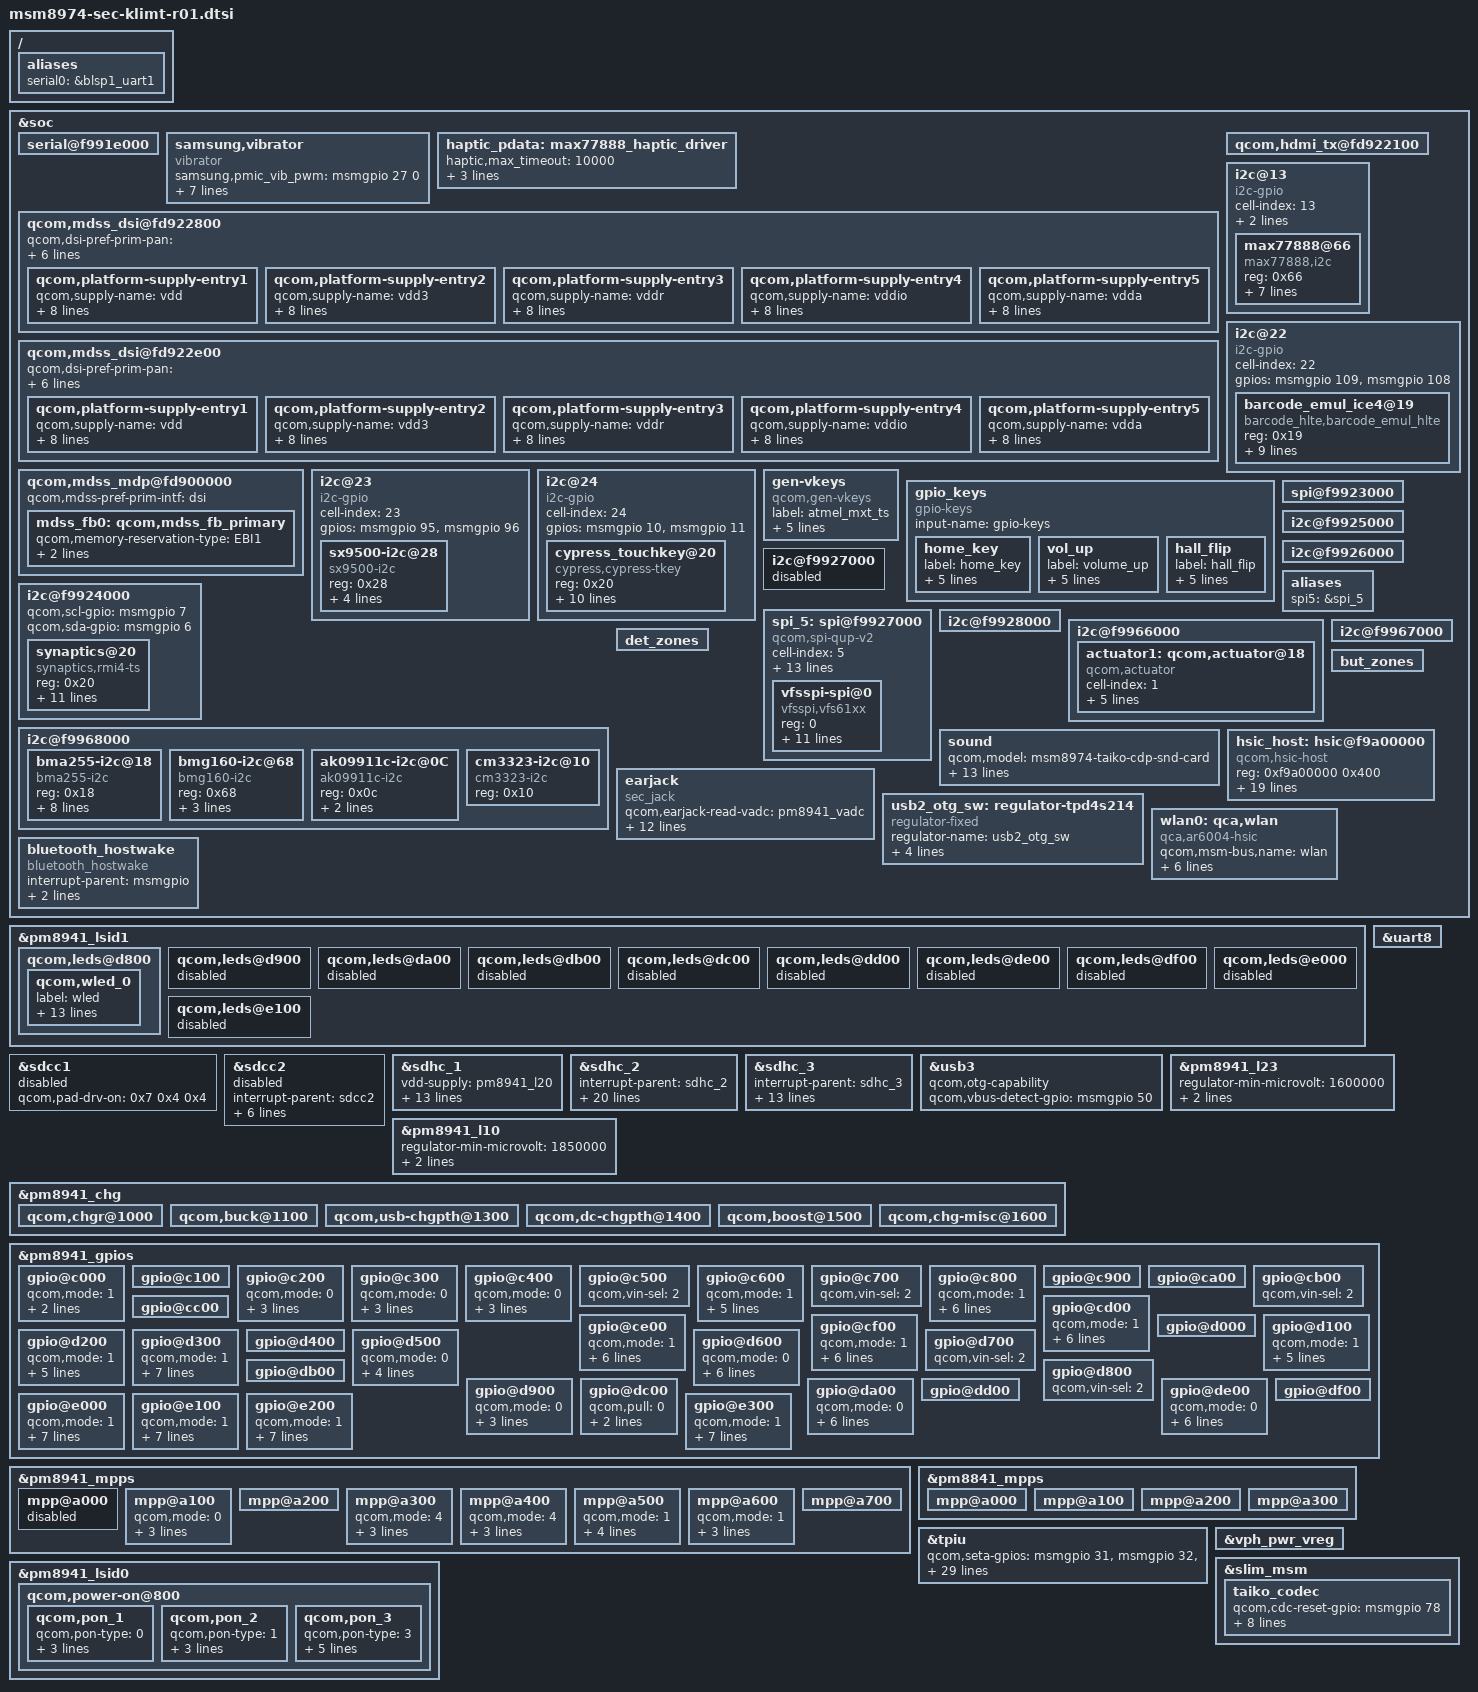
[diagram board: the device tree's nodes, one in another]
/* Copyright (c) 2012-2013, The Linux Foundation. All rights reserved.
 *
 * This program is free software; you can redistribute it and/or modify
 * it under the terms of the GNU General Public License version 2 and
 * only version 2 as published by the Free Software Foundation.
 *
 * This program is distributed in the hope that it will be useful,
 * but WITHOUT ANY WARRANTY; without even the implied warranty of
 * MERCHANTABILITY or FITNESS FOR A PARTICULAR PURPOSE.  See the
 * GNU General Public License for more details.
 */

/include/ "msm8974-leds.dtsi"
/include/ "msm8974-camera-sensor-klimt-r00.dtsi"
/include/ "msm8974-sii8240_mhl-mondrian-r00.dtsi"
/include/ "msm8974-sec-klimt-battery.dtsi"

/ {
	aliases {
		serial0 = &blsp1_uart1;
	};
};

&soc {
	serial@f991e000 {
		status = "ok";
	};

	samsung,vibrator {
		compatible = "vibrator";
		samsung,pmic_vib_pwm = <&msmgpio 27 0>;
		samsung,vib_power_en = <&msmgpio 91 0>;
		samsung,vib_model = <1>;
		samsung,pmic_vib_en = <0>;
		samsung,pmic_haptic_pwr_en = <0>;
		samsung,is_pmic_vib_pwm = <0>;
		samsung,pwm_period_us = <40>;
		samsung,duty_us = <36>;
		status = "ok";
	};
	haptic_pdata: max77888_haptic_driver{
		haptic,max_timeout = <10000>;
		haptic,duty = <44000>;
		haptic,period = <44642>;
		haptic,pwm_id = <1>;
	};
	qcom,mdss_dsi@fd922800 {
		qcom,dsi-pref-prim-pan = <&dsi_dual_2560p_cmd_s6e3ha1_right>;
		vdd-supply = <&pm8941_l22>;
		vdd3-supply = <&pm8941_lvs1>;
		vddr-supply = <&pm8941_l23>;
		vddio-supply = <&pm8941_l12>;
		vdda-supply = <&pm8941_l2>;
		qcom,platform-supply-entry1 {
				qcom,supply-name = "vdd";
				qcom,supply-min-voltage = <3000000>;
				qcom,supply-max-voltage = <3000000>;
				qcom,supply-enable-load = <100000>;
				qcom,supply-disable-load = <100>;
				qcom,supply-pre-on-sleep = <0>;
				qcom,supply-post-on-sleep = <5>;
				qcom,supply-pre-off-sleep = <0>;
				qcom,supply-post-off-sleep = <0>;
		};
		qcom,platform-supply-entry2 {
				qcom,supply-name = "vdd3";
				qcom,supply-min-voltage = <1800000>;
				qcom,supply-max-voltage = <1800000>;
				qcom,supply-enable-load = <100000>;
				qcom,supply-disable-load = <100>;
				qcom,supply-pre-on-sleep = <0>;
				qcom,supply-post-on-sleep = <5>;
				qcom,supply-pre-off-sleep = <0>;
				qcom,supply-post-off-sleep = <0>;
		};
		qcom,platform-supply-entry3 {
				qcom,supply-name = "vddr";
				qcom,supply-min-voltage = <1600000>;
				qcom,supply-max-voltage = <1600000>;
				qcom,supply-enable-load = <100000>;
				qcom,supply-disable-load = <100>;
				qcom,supply-pre-on-sleep = <0>;
				qcom,supply-post-on-sleep = <5>;
				qcom,supply-pre-off-sleep = <0>;
				qcom,supply-post-off-sleep = <0>;
		};

		qcom,platform-supply-entry4 {
				qcom,supply-name = "vddio";
				qcom,supply-min-voltage = <1800000>;
				qcom,supply-max-voltage = <1800000>;
				qcom,supply-enable-load = <100000>;
				qcom,supply-disable-load = <100>;
				qcom,supply-pre-on-sleep = <0>;
				qcom,supply-post-on-sleep = <5>;
				qcom,supply-pre-off-sleep = <0>;
				qcom,supply-post-off-sleep = <0>;
		};

		qcom,platform-supply-entry5 {
				qcom,supply-name = "vdda";
				qcom,supply-min-voltage = <1200000>;
				qcom,supply-max-voltage = <1200000>;
				qcom,supply-enable-load = <100000>;
				qcom,supply-disable-load = <100>;
				qcom,supply-pre-on-sleep = <0>;
				qcom,supply-post-on-sleep = <0>;
				qcom,supply-pre-off-sleep = <0>;
				qcom,supply-post-off-sleep = <0>;
		};
	};

	qcom,mdss_dsi@fd922e00 {
		qcom,dsi-pref-prim-pan = <&dsi_dual_2560p_cmd_s6e3ha1_left>;
		vdd-supply = <&pm8941_l22>;
		vdd3-supply = <&pm8941_lvs1>;
		vddr-supply = <&pm8941_l23>;
		vddio-supply = <&pm8941_l12>;
		vdda-supply = <&pm8941_l2>;
		qcom,platform-supply-entry1 {
				qcom,supply-name = "vdd";
				qcom,supply-min-voltage = <3000000>;
				qcom,supply-max-voltage = <3000000>;
				qcom,supply-enable-load = <100000>;
				qcom,supply-disable-load = <100>;
				qcom,supply-pre-on-sleep = <0>;
				qcom,supply-post-on-sleep = <5>;
				qcom,supply-pre-off-sleep = <0>;
				qcom,supply-post-off-sleep = <0>;
		};
		qcom,platform-supply-entry2 {
				qcom,supply-name = "vdd3";
				qcom,supply-min-voltage = <1800000>;
				qcom,supply-max-voltage = <1800000>;
				qcom,supply-enable-load = <100000>;
				qcom,supply-disable-load = <100>;
				qcom,supply-pre-on-sleep = <0>;
				qcom,supply-post-on-sleep = <5>;
				qcom,supply-pre-off-sleep = <0>;
				qcom,supply-post-off-sleep = <0>;
		};
		qcom,platform-supply-entry3 {
				qcom,supply-name = "vddr";
				qcom,supply-min-voltage = <1600000>;
				qcom,supply-max-voltage = <1600000>;
				qcom,supply-enable-load = <100000>;
				qcom,supply-disable-load = <100>;
				qcom,supply-pre-on-sleep = <0>;
				qcom,supply-post-on-sleep = <5>;
				qcom,supply-pre-off-sleep = <0>;
				qcom,supply-post-off-sleep = <0>;
		};

		qcom,platform-supply-entry4 {
				qcom,supply-name = "vddio";
				qcom,supply-min-voltage = <1800000>;
				qcom,supply-max-voltage = <1800000>;
				qcom,supply-enable-load = <100000>;
				qcom,supply-disable-load = <100>;
				qcom,supply-pre-on-sleep = <0>;
				qcom,supply-post-on-sleep = <5>;
				qcom,supply-pre-off-sleep = <0>;
				qcom,supply-post-off-sleep = <0>;
		};

		qcom,platform-supply-entry5 {
				qcom,supply-name = "vdda";
				qcom,supply-min-voltage = <1200000>;
				qcom,supply-max-voltage = <1200000>;
				qcom,supply-enable-load = <100000>;
				qcom,supply-disable-load = <100>;
				qcom,supply-pre-on-sleep = <0>;
				qcom,supply-post-on-sleep = <0>;
				qcom,supply-pre-off-sleep = <0>;
				qcom,supply-post-off-sleep = <0>;
		};
	};

	qcom,mdss_mdp@fd900000 {
		qcom,mdss-pref-prim-intf = "dsi";
		mdss_fb0: qcom,mdss_fb_primary {
			qcom,memory-reservation-type = "EBI1";
			qcom,memblock-reserve = <0x03200000 0x01F00000>;
			qcom,mdss-fb-split = <800 800>;
		};
	};

	qcom,hdmi_tx@fd922100 {
		status = "ok";
	};

    i2c@13 {
        cell-index = <13>;
        compatible = "i2c-gpio";
        gpios = <&msmgpio 83 0 /* sda */
                 &msmgpio 84 0 /* scl */
                >;
		i2c-gpio,delay-us = <2>;
		#address-cells = <1>;
		#size-cells = <0>;
		max77888@66 {
		    compatible = "max77888,i2c";
		    reg = <0x66>;
		    interrupt-parent = <&pm8941_gpios>;
		    interrupts = <23 0>,
		    		 <27 0>;
		    max77888,irq-gpio = <&pm8941_gpios 23 0x00>;
		    max77888,irq-reset-gpio = <&pm8941_gpios 27 0x00>;
		    max77888,irq-base = <357>;
		    max77888,wakeup = <1>;
		    max77888,haptic = <&haptic_pdata>;
		};
    };

	i2c@22 {
		cell-index = <22>;
		compatible = "i2c-gpio";
		gpios = <&msmgpio 109 0 /* sda */
		&msmgpio 108 0 /* scl */
		>;

		barcode_emul_ice4@19 {
			compatible = "barcode_hlte,barcode_emul_hlte";
			reg = <0x19>;
			interrupt-parent = <&msmgpio>;
			interrupts = <64 0>;
			vdd-supply = <&pm8941_l19>;
			barcode,cresetb = <&msmgpio 57 0x01>;
			barcode,reset_n = <&msmgpio 132 0x00>;
			barcode,scl-gpio = <&msmgpio 108 0x00>;
			barcode,sda-gpio = <&msmgpio 109 0x00>;
			barcode,irq-gpio = <&msmgpio 64 0x00>;
			barcode,i2c-pull-up = <1>;
		};
	};

	i2c@23 {
		cell-index = <23>;
		compatible = "i2c-gpio";
		gpios = <&msmgpio 95 0 /* sda */
		&msmgpio 96 0 /* scl */
		>;
		sx9500-i2c@28 {
			compatible = "sx9500-i2c";
			reg = <0x28>;
			sx9500-i2c,nirq-gpio = <&pm8941_mpps 2 0x00>;
			sx9500-i2c,scl-gpio = <&msmgpio 96 0x00>;
			sx9500-i2c,sda-gpio = <&msmgpio 95 0x00>;
			sx9500-i2c,i2c-pull-up = <1>;
		};
	};

	i2c@24 {
		cell-index = <24>;
		compatible = "i2c-gpio";
		gpios = <&msmgpio 10 0 /* sda */
				&msmgpio 11 0 /* scl */
		>;


		cypress_touchkey@20 {
			compatible = "cypress,cypress-tkey";
			reg = <0x20>;
			interrupt-parent = <&msmgpio>;
			interrupts = <144 0>;
			vdd_led-supply = <&pm8941_l19>;
			vcc_en-supply = <&pm8941_l10>;
			vdd_led-gpio = <&pm8941_gpios 12 0x00>; /* TCON_EN */
			cypress,scl-gpio = <&msmgpio 11 0x00>;
			cypress,sda-gpio = <&msmgpio 10 0x00>;
			cypress,irq-gpio = <&msmgpio 144 0x1>;
			cypress,tkey-keycodes = <254 158>;
			cypress,i2c-pull-up = <1>;
		};

/*
		i2c-gpio,delay-us = <4>;

		lp8556_backlight@2C {
				compatible = "lp8556,backlight-control";
				reg = <0x2C>;
				lp8556,en-gpio = <&pm8941_gpios 19 0x00>;
				lp8556,scl-gpio = <&msmgpio 11 0x00>;
				lp8556,sda-gpio = <&msmgpio 10 0x00>;
		};
*/
	};

	qcom,hdmi_tx@fd922100 {
		status = "ok";
	};



	gen-vkeys {
		compatible = "qcom,gen-vkeys";
		label = "atmel_mxt_ts";
		qcom,disp-maxx = <720>;
		qcom,disp-maxy = <1280>;
		qcom,panel-maxx = <760>;
		qcom,panel-maxy = <1424>;
		qcom,key-codes = <158 139 102 217>;
	};

	gpio_keys {
		compatible = "gpio-keys";
		input-name = "gpio-keys";

		home_key {
			label = "home_key";
			gpios = <&pm8941_gpios 3 0x1>;
			linux,input-type = <1>;
			linux,code = <172>;
			gpio-key,wakeup;
			debounce-interval = <15>;
		};
/*
		vol_down {
			label = "volume_down";
			gpios = <&pm8941_gpios 2 0x1>;
			linux,input-type = <1>;
			linux,code = <114>;
			gpio-key,wakeup;
			debounce-interval = <15>;
		};
*/
		vol_up {
			label = "volume_up";
			gpios = <&pm8941_gpios 5 0x1>;
			linux,input-type = <1>;
			linux,code = <115>;
			gpio-key,wakeup;
			debounce-interval = <15>;
		};

		hall_flip {
			label = "hall_flip";
			gpios = <&pm8941_gpios 31 0>;
			linux,input-type = <1>;
			linux,code = <0x15>;
			gpio-key,wakeup;
			debounce-interval = <15>;
		};
	};

	/* BLSP#1 */
	spi@f9923000 {
		status = "okay";
	};

	/* BLSP#2 */
	i2c@f9924000 {
		status = "okay";
		qcom,scl-gpio = <&msmgpio 7 0>;
		qcom,sda-gpio = <&msmgpio 6 0>;
		synaptics@20 {
			compatible = "synaptics,rmi4-ts";
			reg = <0x20>;
			interrupt-parent = <&pm8941_gpios>;
			interrupts = <30 0>;
			synaptics,supply-num = <1>;			/* the number of regulators */
			synaptics,supply-name = "8941_l10";	/* the name of regulators, in power-on order */
			synaptics,external_ldo = <&pm8941_gpios 10 0x1>;
			synaptics,irq-gpio = <&pm8941_gpios 30 0x1>;
			synaptics,reset-gpio = <&pm8941_gpios 20 0x1>;
			synaptics,i2c-pull-up = <1>;
			synaptics,tsp-project = "Klimt";
			synaptics,tsp-coords = <1599 2559>;
			synaptics,tsp-extra_config = <0 0 0 0>; /* <"pwrctrl", "N", "N", "N"> */
			/* Set regulators' voltage below. Search with "8941_l22", "8941_l10" */
		};
	};

	/* BLSP#3 */
	i2c@f9925000 {
	};

	/* BLSP#4 */
	i2c@f9926000 {
	};

	/* BLSP#5 */
	i2c@f9927000 {
		status = "disabled";
	};
	aliases {
		spi5 = &spi_5;
	};
	spi_5: spi@f9927000 {
		status = "okay";
		compatible = "qcom,spi-qup-v2";
		cell-index = <5>;
		#address-cells = <1>;
		#size-cells = <0>;
		reg = <0xf9927000 0x1000>,
			<0xf9904000 0x19000>;
		reg-names = "spi_physical", "spi_bam_physical";
		interrupt-names = "spi_irq", "spi_bam_irq";
		interrupts = <0 99 0>, <0 238 0>;
		spi-max-frequency = <19200000>;

		qcom,gpio-mosi = <&msmgpio 23 0>;
		qcom,gpio-miso = <&msmgpio 24 0>;
		qcom,gpio-clk  = <&msmgpio 26 0>;
		qcom,gpio-cs0  = <&msmgpio 25 0>;

		qcom,infinite-mode = <0>;
		qcom,use-bam;
		qcom,ver-reg-exists;
		qcom,bam-consumer-pipe-index = <20>;
		qcom,bam-producer-pipe-index = <21>;
		qcom,master-id = <86>;

		vfsspi-spi@0 {
			compatible = "vfsspi,vfs61xx";
			reg = <0>;
			spi-max-frequency = <19200000>;
			vfsspi-sleepPin = <&msmgpio 73 0x00>;
			vfsspi-drdyPin = <&msmgpio 94 0x01>;
			vfsspi-ldoPin = <&pm8941_gpios 18 0x00>; /* LDO_EN_1.8V */
			vfsspi-ldoPin2 = <&pm8941_gpios 19 0x00>; /* LDO_EN_3.3V */
			/* vfsspi-ocpflag = <&pm8941_gpios 7 0x00>; */
			/* vfsspi-ocpen = <&msmgpio 63 0x00>; */
			vfsspi-mosipin = <23>;
			vfsspi-misopin = <24>;
			vfsspi-cspin = <25>;
			vfsspi-clkpin = <26>;
			vfsspi-orient = <0>;
			vfsspi-ldocontrol= <1>;
			};
	};

	/* BLSP#6 */
	i2c@f9928000 {
		status = "okay";
	};

	/* BLSP#7 */
	/* i2c@f9963000 {
	}; */

	/* BLSP#8 */
	/* i2c@f9964000 {
	}; */

	/* BLSP#10 */
	i2c@f9966000 {
		actuator1: qcom,actuator@18 {
			compatible = "qcom,actuator";
			cell-index = <1>;
			reg = <0x18>;
			gpios = <&msmgpio 55 0>,
					<&msmgpio 56 0>;
			qcom,gpio-req-tbl-num = <0 1>;
			qcom,gpio-req-tbl-flags = <1 1>;
			qcom,gpio-req-tbl-label = "I2C_DATA0",
							  		"I2C_CLK0";
		};
	};

	/* BLSP#11 */
	i2c@f9967000 {
	};

	/* BLSP#12 */
	i2c@f9968000 {
		status = "okay";
		bma255-i2c@18 {
			compatible = "bma255-i2c";
			reg = <0x18>;
			interrupt-parent = <&msmgpio>;
			interrupts = <86 0>;
			bma255-i2c,scl = <&msmgpio 88 0>;
			bma255-i2c,sda = <&msmgpio 87 0>;
			bma255-i2c,acc_int1-gpio = <&msmgpio 86 0x00>;
			bma255-i2c,chip_pos = <4>;
			bma255-i2c,vdd-supply = <&pm8941_l18>;
			bma255-i2c,vdd-io-supply = <&pm8941_lvs1>;
		};
		bmg160-i2c@68 {
			compatible = "bmg160-i2c";
			reg = <0x68>;
			interrupt-parent = <&msmgpio>;
			interrupts = <74 0>;
			bmg160-i2c,chip_pos = <4>;
		};
		ak09911c-i2c@0C {
			compatible = "ak09911c-i2c";
			reg = <0x0c>;
			ak09911c-i2c,m_rst_n-gpio = <&msmgpio 80 0x01>;
			ak09911c-i2c,chip_pos = <5>;
		};
		cm3323-i2c@10 {
			compatible = "cm3323-i2c";
			reg = <0x10>;
		};
	};

	sound {
		qcom,model = "msm8974-taiko-cdp-snd-card";
		qcom,hdmi-audio-rx;
		qcom,mainmic-bias-gpio = <&pm8941_gpios 33 0>;
		qcom,submic-bias-gpio = <&pm8941_gpios 35 0>;
		qcom,spkamp-en-gpio = <&msmgpio 82 0>;

		qcom,audio-routing =
			"RX_BIAS", "MCLK",
			"LDO_H", "MCLK",
			"AIF4 MAD", "MCLK",
			"Lineout_1 amp", "LINEOUT1",
			"Lineout_2 amp", "LINEOUT2",
			"Lineout_3 amp", "LINEOUT3",
			"Lineout_4 amp", "LINEOUT4",
			"AMIC4", "Main Mic Bias",
			"Main Mic Bias", "Main Mic",
			"AMIC2", "MIC BIAS2 External",
			"MIC BIAS2 External", "Headset Mic",
			"AMIC3", "Sub Mic Bias",
			"Sub Mic Bias", "Sub Mic";
	};

	det_zones: det_zones {
		#list-det-cells = <4>;
	};

	but_zones: but_zones {
		#list-but-cells = <3>;
	};

	earjack {
		compatible = "sec_jack";
		qcom,earjack-read-vadc = <&pm8941_vadc>;
		qcom,earjack-detect-gpio = <&pm8941_gpios 22 0>;
		qcom,earjack-micbias-gpio = <&pm8941_gpios 34 0>;
		qcom,earjack-sendend-gpio = <&msmgpio 77 0>;
		qcom,earjack-fsa_en-gpio = <&msmgpio 8 1>;
		qcom,send-end-active-high;

		det-zones-list = <&det_zones 0 10000 10 0>,
						 <&det_zones 900 10000 10 0>,
						 <&det_zones 2400 10000 10 1>,
						 <&det_zones 9999 10000 10 1>;
		but-zones-list = <&but_zones 0 0 155>,
						 <&but_zones 1 156 310>,
						 <&but_zones 2 311 800>;
		mpp-channel-scaling = <4 1 3>;
	};

	usb2_otg_sw: regulator-tpd4s214 {
		compatible = "regulator-fixed";
		regulator-name = "usb2_otg_sw";
		gpio = <&pm8941_gpios 18 0>;
		parent-supply = <&pm8941_boost>;
		startup-delay-us = <17000>;
		enable-active-high;
	};

	hsic_host: hsic@f9a00000 {
		compatible = "qcom,hsic-host";
		reg = <0xf9a00000 0x400>;
		#address-cells = <0>;
		interrupt-parent = <&hsic_host>;
		interrupts = <0 1 2>;
		#interrupt-cells = <1>;
		interrupt-map-mask = <0xffffffff>;
		interrupt-map = <0 &intc 0 136 0
			1 &intc 0 148 0
			2 &msmgpio 144 0x8>;
		interrupt-names = "core_irq", "async_irq", "wakeup";
		HSIC_VDDCX-supply = <&pm8841_s2>;
		HSIC_GDSC-supply = <&gdsc_usb_hsic>;
		hsic,strobe-gpio = <&msmgpio 144 0x00>;
		hsic,data-gpio = <&msmgpio 145 0x00>;
		hsic,resume-gpio = <&msmgpio 80 0x00>;
		hsic,ignore-cal-pad-config;
		hsic,strobe-pad-offset = <0x2050>;
		hsic,data-pad-offset = <0x2054>;
		qcom,phy-susp-sof-workaround;

		qcom,msm-bus,name = "hsic";
		qcom,msm-bus,num-cases = <2>;
		qcom,msm-bus,num-paths = <1>;
		qcom,msm-bus,vectors-KBps =
				<85 512 0 0>,
				<85 512 40000 160000>;
        };

	wlan0: qca,wlan {
		compatible = "qca,ar6004-hsic";
		qcom,msm-bus,name = "wlan";
		qcom,msm-bus,num-cases = <5>;
		qcom,msm-bus,active-only = <0>;
		qcom,msm-bus,num-paths = <1>;
		qcom,msm-bus,vectors-KBps =
				<85 512 0 0>,
				<85 512 40000 160000>,
				<85 512 40000 320000>,
				<85 512 40000 480000>,
				<85 512 40000 800000>;
	};
	bluetooth_hostwake{
		compatible = "bluetooth_hostwake";
		interrupt-parent = <&msmgpio>;
		interrupts = <75 0>;
		bluetooth_hostwake,irq-gpio = <&msmgpio 75 0x00>;
	};
};

&pm8941_lsid1 {
	qcom,leds@d800 {
		status = "okay";
		qcom,wled_0 {
			label = "wled";
			linux,name = "wled:backlight";
			linux,default-trigger = "bkl-trigger";
			qcom,cs-out-en;
			qcom,op-fdbck = <1>;
			qcom,default-state = "off";
			qcom,max-current = <25>;
			qcom,ctrl-delay-us = <0>;
			qcom,boost-curr-lim = <5>;
			qcom,cp-sel = <0>;
			qcom,switch-freq = <11>;
			qcom,ovp-val = <2>;
			qcom,num-strings = <3>;
			qcom,id = <0>;
		};
	};

	qcom,leds@d900 {
		status = "disabled";
	};

	qcom,leds@da00 {
		status = "disabled";
	};

	qcom,leds@db00 {
		status = "disabled";
	};

	qcom,leds@dc00 {
		status = "disabled";
	};

	qcom,leds@dd00 {
		status = "disabled";
	};

	qcom,leds@de00 {
		status = "disabled";
	};

	qcom,leds@df00 {
		status = "disabled";
	};

	qcom,leds@e000 {
		status = "disabled";
	};

	qcom,leds@e100 {
		status = "disabled";
	};
};

&sdcc1 {
       status = "disabled";
};

&sdcc2 {
	#address-cells = <0>;
	interrupt-parent = <&sdcc2>;
	interrupts = <0 1 2>;
	#interrupt-cells = <1>;
	interrupt-map-mask = <0xffffffff>;
	interrupt-map = <0 &intc 0 125 0
			1 &intc 0 220 0
			2 &msmgpio 62 0x3>;
	interrupt-names = "core_irq", "bam_irq", "status_irq";
	cd-gpios = <&msmgpio 62 0x1>;
	status = "disabled";
};

&sdhc_1 {
	vdd-supply = <&pm8941_l20>;
	vdd-io-supply = <&pm8941_s3>;

	qcom,vdd-always-on;
	qcom,vdd-lpm-sup;
	qcom,vdd-voltage-level = <2950000 2950000>;
	qcom,vdd-current-level = <800 500000>;

	qcom,vdd-io-always-on;
	qcom,vdd-io-voltage-level = <1800000 1800000>;
	qcom,vdd-io-current-level = <250 154000>;

	qcom,pad-pull-on = <0x0 0x3 0x3>; /* no-pull, pull-up, pull-up */
	qcom,pad-pull-off = <0x0 0x3 0x3>; /* no-pull, pull-up, pull-up */
	qcom,pad-drv-on = <0x4 0x4 0x4>; /* 10mA, 10mA, 10mA */
	qcom,pad-drv-off = <0x0 0x0 0x0>; /* 2mA, 2mA, 2mA */

	qcom,nonremovable;
	status = "ok";
};

&sdhc_2 {
	#address-cells = <0>;
	interrupt-parent = <&sdhc_2>;
	interrupts = <0 1>;
	#interrupt-cells = <1>;
	interrupt-map-mask = <0xffffffff>;
	interrupt-map = <0 &intc 0 125 0
			1 &intc 0 221 0>;
	interrupt-names = "hc_irq", "pwr_irq";
	//cd-gpios = <&msmgpio 62 0x1>;

	vdd-supply = <&pm8941_s3>;
	vdd-io-supply = <&pm8941_s3>;

	qcom,vdd-always-on;
	qcom,vdd-voltage-level = <1800000 1800000>;
	qcom,vdd-current-level = <2000 32000>;

	qcom,vdd-io-always-on;
	qcom,vdd-io-voltage-level = <1800000 1800000>;
	qcom,vdd-io-current-level = <2000 32000>;

	qcom,pad-pull-on = <0x0 0x3 0x3>; /* no-pull, pull-up, pull-up */
	qcom,pad-pull-off = <0x0 0x3 0x3>; /* no-pull, pull-up, pull-up */
	qcom,pad-drv-on = <0x7 0x4 0x3>; /* 16mA, 10mA, 8mA */
	qcom,pad-drv-off = <0x0 0x0 0x0>; /* 2mA, 2mA, 2mA */

	qcom,current-limit = <32000>;

	qcom,clk-rates = <400000 20000000 25000000 50000000 100000000 200000000>;

	qcom,sup-voltages = <2950 2950>;

	status-cb = <2>;
	status = "ok";
};

&sdhc_3 {
	#address-cells = <0>;
	interrupt-parent = <&sdhc_3>;
	interrupts = <0 1 2>;
	#interrupt-cells = <1>;
	interrupt-map-mask = <0xffffffff>;
	interrupt-map = <0 &intc 0 127 0
			1 &intc 0 224 0
			2 &msmgpio 62 0x3>;
	interrupt-names = "hc_irq", "pwr_irq", "status_irq";

	vdd-supply = <&pm8941_l21>;
	vdd-io-supply = <&pm8941_l21>;

	qcom,vdd-voltage-level = <2950000 2950000>;
	qcom,vdd-current-level = <9000 800000>;
	qcom,vdd-io-voltage-level = <2950000 2950000>;
	qcom,vdd-io-current-level = <6 22000>;
	qcom,sup-voltages = <2950 2950>;

	cd-gpios = <&msmgpio 62 0x1>;
	wp-gpios = <&pm8941_gpios 29 0x1>;

	status = "ok";
};

/* Drive strength recommendations for clock line from hardware team is 10 mA.
 * But since the driver has been been using the below values from the start
 * without any problems, continue to use those.
 */
&sdcc1 {
	qcom,pad-drv-on = <0x7 0x4 0x4>; /* 16mA, 10mA, 10mA */
};

&sdcc2 {
	qcom,pad-drv-on = <0x7 0x4 0x4>; /* 16mA, 10mA, 10mA */
};

&sdhc_1 {
	qcom,pad-drv-on = <0x7 0x4 0x4>; /* 16mA, 10mA, 10mA */
};

&sdhc_2 {
	qcom,pad-drv-on = <0x7 0x4 0x3>; /* 16mA, 10mA, 8mA */
};

&uart8 {
	status = "ok";
};

&usb3 {
	qcom,otg-capability;
	qcom,vbus-detect-gpio = <&msmgpio 50 0>;
};

&pm8941_l23 {
/* OCTA 1.6V VDDR regulator */
	regulator-min-microvolt = <1600000>;
	regulator-max-microvolt = <1600000>;
	qcom,init-voltage = <1600000>;
};

&pm8941_l10 {
/* TSP 1.8V IO regulator */
	regulator-min-microvolt = <1850000>;
	regulator-max-microvolt = <1850000>;
	qcom,init-voltage = <1850000>;
};

&pm8941_chg {
	status = "ok";

	qcom,chgr@1000 {
		status = "ok";
	};

	qcom,buck@1100 {
		status = "ok";
	};

	qcom,usb-chgpth@1300 {
		status = "ok";
	};

	qcom,dc-chgpth@1400 {
		status = "ok";
	};

	qcom,boost@1500 {
		status = "ok";
	};

	qcom,chg-misc@1600 {
		status = "ok";
	};
};

&pm8941_gpios {
	gpio@c000 { /* GPIO 1 */
		/* CAM_MOVIE_EN pin */
		qcom,mode = <1>;	/* DIG_OUT */
		qcom,pull = <4>;	/* QPNP_PIN_PULL_DOWN */
		qcom,vin-sel = <2>;		/* PM8941 S3 = 1.8 V */
	};

	gpio@c100 { /* GPIO 2 */
	};

	gpio@c200 { /* GPIO 3 */
		qcom,mode = <0>;
		qcom,pull = <0>;
		qcom,vin-sel = <2>;
		qcom,src-sel = <0>;
	};

	gpio@c300 { /* GPIO 4 */
		qcom,mode = <0>;
		qcom,pull = <0>;
		qcom,vin-sel = <2>;
		qcom,src-sel = <0>;
	};

	gpio@c400 { /* GPIO 5 */
		qcom,mode = <0>;
		qcom,pull = <0>;
		qcom,vin-sel = <2>;
		qcom,src-sel = <0>;
	};

	gpio@c500 { /* GPIO 6 */
		/* VT_CAM_STBY */
		qcom,vin-sel = <2>;		/* QPNP_PIN_VIN2 */
	};

	gpio@c600 { /* GPIO 7 */
		/* fingerprint sensor OCP_FLAG */
		qcom,mode = <1>;			/* Digital output */
		qcom,output-type = <0>;
		qcom,vin-sel = <2>;
		qcom,out-strength = <1>;	/* Low drive strength */
		qcom,src-sel = <0>;
		qcom,master-en = <1>;		/* Enable GPIO */
	};

	gpio@c700 { /* GPIO 8 */
		/* 2M_A2.8V_EN */
		qcom,vin-sel = <2>;		/* PM8941 S3 = 1.8 V */
	};

	gpio@c800 { /* GPIO 9 */
		qcom,mode = <1>;  /* QPNP_PIN_MODE_DIG_OUT */
		qcom,output-type = <0>; /* QPNP_PIN_OUT_BUF_CMOS */
		qcom,pull = <5>; /* QPNP_PIN_PULL_NO */
		qcom,vin-sel = <2>; /* QPNP_PIN_VIN2 */
		qcom,out-strength = <3>; /* QPNP_PIN_OUT_STRENGTH_HIGH */
		qcom,src-sel = <0>; /* QPNP_PIN_SEL_FUNC_CONSTANT */
		qcom,master-en = <1>;
	};

	gpio@c900 { /* GPIO 10 */
	};

	gpio@ca00 { /* GPIO 11 */
	};

	gpio@cb00 { /* GPIO 12 */
		/* 8M_AVDD_LDO_EN */
		qcom,vin-sel = <2>;		/* PM8941 S3 = 1.8 V */
	};

	gpio@cc00 { /* GPIO 13 */
	};

	gpio@cd00 { /* GPIO 14 */
		qcom,mode = <1>;  /* QPNP_PIN_MODE_DIG_OUT */
		qcom,output-type = <0>; /* QPNP_PIN_OUT_BUF_CMOS */
		qcom,pull = <5>; /* QPNP_PIN_PULL_NO */
		qcom,vin-sel = <2>; /* QPNP_PIN_VIN2 */
		qcom,out-strength = <3>; /* QPNP_PIN_OUT_STRENGTH_HIGH */
		qcom,src-sel = <0>; /* QPNP_PIN_SEL_FUNC_CONSTANT */
		qcom,master-en = <1>;
	};

	gpio@ce00 { /* GPIO 15 */
		qcom,mode = <1>;
		qcom,output-type = <0>;
		qcom,pull = <5>;
		qcom,vin-sel = <2>;
		qcom,out-strength = <1>;
		qcom,src-sel = <2>;
		qcom,master-en = <1>;
	};

	gpio@cf00 { /* GPIO 16 used for BT sleep_clk*/
		qcom,mode = <1>;
		qcom,output-type = <0>;
		qcom,pull = <5>;
		qcom,out-strength = <3>;
		qcom,vin-sel = <2>;
		qcom,src-sel = <3>;
		qcom,master_en = <1>;
	};

	gpio@d000 { /* GPIO 17 */
	};

	gpio@d100 { /* GPIO 18 */
		/* fingerprint sensor BTP_LDO_EN */
		qcom,mode = <1>;			/* Digital output */
		qcom,output-type = <0>;
		qcom,vin-sel = <2>;
		qcom,out-strength = <1>;	/* Low drive strength */
		qcom,src-sel = <0>;
		qcom,master-en = <1>;		/* Enable GPIO */
	};

	gpio@d200 { /* GPIO 19 */
		/* fingerprint sensor BTP_LDO_EN2 */
		qcom,mode = <1>;			/* Digital output */
		qcom,output-type = <0>;
		qcom,vin-sel = <2>;
		qcom,out-strength = <1>;	/* Low drive strength */
		qcom,src-sel = <0>;
		qcom,master-en = <1>;		/* Enable GPIO */
	};

	gpio@d300 { /* GPIO 20 */
		qcom,mode = <1>;		/* QPNP_PIN_MODE_DIG_OUT */
		qcom,output-type = <0>;		/* QPNP_PIN_OUT_BUF_CMOS */
		qcom,invert = <0>;		/* Output low initially */
		qcom,pull = <5>;		/* QPNP_PIN_PULL_NO */
		qcom,vin-sel = <2>;		/* QPNP_PIN_VIN2 */
		qcom,out-strength = <3>;	/* QPNP_PIN_OUT_STRENGTH_HIGH */
		qcom,src-sel = <0>;		/* QPNP_PIN_SEL_FUNC_CONSTANT */
		qcom,master-en = <1>;		/* Enable GPIO */
	};

	gpio@d400 { /* GPIO 21 */
	};

	gpio@d500 { /* GPIO 22 */
		qcom,mode = <0>;	/* input */
		qcom,pull = <5>;		/* pull-up with 30uA current strength */
		qcom,vin-sel = <2>;	/* VIN=S3 */
		qcom,src-sel = <0>;	/* constant */
		qcom,master_en = <1>;
	};

	gpio@d600 { /* GPIO 23 */
		qcom,mode = <0>;		/* QPNP_PIN_MODE_DIG_IN */
		qcom,output-type = <0>;		/* QPNP_PIN_OUT_BUF_CMOS */
		qcom,pull = <5>;		/* QPNP_PIN_PULL_NO */
		qcom,vin-sel = <2>; 		/* QPNP_PIN_VIN2 */
		qcom,out-strength = <3>;	/* QPNP_PIN_OUT_STRENGTH_HIGH */
		qcom,src-sel = <0>;		/* QPNP_PIN_SEL_FUNC_CONSTANT*/
		qcom,master-en = <1>;
	};

	gpio@d700 { /* GPIO 24 */
		/* VT sensor rst pin */
		qcom,vin-sel = <2>;		/* PM8941 S3 = 1.8 V */
	};

	gpio@d800 { /* GPIO 25 */
		/* 8M sensor rst pin */
		qcom,vin-sel = <2>;		/* PM8941 S3 = 1.8 V */
	};

	gpio@d900 { /* GPIO 26 */
		qcom,mode = <0>;		/* QPNP_PIN_MODE_DIG_IN */
		qcom,pull = <5>;		/* QPNP_PIN_PULL_NO */
		qcom,vin-sel = <2>;		/* QPNP_PIN_VIN2 */
		qcom,src-sel = <0>;		/* QPNP_PIN_SEL_FUNC_CONSTANT */
	};

	gpio@da00 { /* GPIO 27 */
		qcom,mode = <0>;		/* QPNP_PIN_MODE_DIG_IN */
		qcom,output-type = <0>;		/* QPNP_PIN_OUT_BUF_CMOS */
		qcom,pull = <5>;		/* QPNP_PIN_PULL_NO */
		qcom,vin-sel = <2>; 		/* QPNP_PIN_VIN2 */
		qcom,out-strength = <3>;	/* QPNP_PIN_OUT_STRENGTH_HIGH */
		qcom,src-sel = <0>;		/* QPNP_PIN_SEL_FUNC_CONSTANT*/
		qcom,master-en = <1>;
	};

	gpio@db00 { /* GPIO 28 */
	};

	gpio@dc00 { /* GPIO 29 */
		qcom,pull = <0>; /* set to default pull */
		qcom,master-en = <1>;
		qcom,vin-sel = <2>; /* select 1.8 V source */
	};

	gpio@dd00 { /* GPIO 30 */
	};

	gpio@de00 { /* GPIO 31 */
		qcom,mode = <0>;
		qcom,output-type = <0>;
		qcom,vin-sel = <2>;
		qcom,out-strength = <2>;
		qcom,src-sel = <3>;
		qcom,pull = <5>;
		qcom,master-en = <1>;
	};

	gpio@df00 { /* GPIO 32 */
	};

	gpio@e000 { /* GPIO 33 */
		qcom,mode = <1>;		/* Digital output */
		qcom,output-type = <0>;	/* CMOS logic */
		qcom,pull = <5>;			/* QPNP_PIN_PULL_NO */
		qcom,invert = <0>;		/* Output low initially */
		qcom,vin-sel = <2>;		/* PM8941 S3 = 1.8 V */
		qcom,src-sel = <0>;		/* Constant */
		qcom,out-strength = <2>;	/* Medium drive strength */
		qcom,master-en = <1>;	/* Enable GPIO */
	};

	gpio@e100 { /* GPIO 34 */
		qcom,mode = <1>;		/* Digital output */
		qcom,output-type = <0>;	/* CMOS logic */
		qcom,pull = <5>;			/* QPNP_PIN_PULL_NO */
		qcom,invert = <0>;		/* Output low initially */
		qcom,vin-sel = <2>;		/* PM8941 S3 = 1.8 V */
		qcom,src-sel = <0>;		/* Constant */
		qcom,out-strength = <2>;	/* Medium drive strength */
		qcom,master-en = <1>;	/* Enable GPIO */
	};

	gpio@e200 { /* GPIO 35 */
		qcom,mode = <1>;		/* Digital output */
		qcom,output-type = <0>;	/* CMOS logic */
		qcom,pull = <5>;			/* QPNP_PIN_PULL_NO */
		qcom,invert = <0>;		/* Output low initially */
		qcom,vin-sel = <2>;		/* PM8941 S3 = 1.8 V */
		qcom,src-sel = <0>;		/* Constant */
		qcom,out-strength = <2>;	/* Medium drive strength */
		qcom,master-en = <1>;	/* Enable GPIO */
	};

	gpio@e300 { /* GPIO 36 */
		qcom,mode = <1>;  /* QPNP_PIN_MODE_DIG_OUT */
		qcom,output-type = <0>; /* QPNP_PIN_OUT_BUF_CMOS */
		qcom,invert = <0>;	/* QPNP_PIN_INVERT_DISABLE */
		qcom,pull = <5>; /* QPNP_PIN_PULL_NO */
		qcom,vin-sel = <2>; /* QPNP_PIN_VIN2 */
		qcom,out-strength = <3>; /* QPNP_PIN_OUT_STRENGTH_HIGH */
		qcom,src-sel = <3>; /* QPNP_PIN_SEL_FUNC_2 */
		qcom,master-en = <1>;
	};
};

&pm8941_mpps {

	mpp@a000 { /* MPP 1 */
		status = "disabled";
	};

	mpp@a100 { /* MPP 2 */
		qcom,mode = <0>; /* DIG_IN */
		qcom,vin-sel = <2>; /* S3A 1.8v */
		qcom,src-sel = <0>; /* CONSTANT */
		qcom,master-en = <1>; /* ENABLE MPP */
	};

	mpp@a200 { /* MPP 3 */
	};

	mpp@a300 { /* MPP 4 */
		qcom,mode = <4>; /* AIN input */
		qcom,ain-route = <3>; /* AMUX 8 */
		qcom,master-en = <1>;/* Enable MPP4 */
		qcom,src-sel = <0>; /* Function constant */
	};

	mpp@a400 { /* MPP 5 */
		qcom,mode = <4>; /* AIN input */
		qcom,ain-route = <0>; /* AMUX 5 */
		qcom,master-en = <1>;/* Enable MPP4 */
		qcom,src-sel = <0>; /* Function constant */
	};

	mpp@a500 { /* MPP 6 */
		/* SPI_ETH_RST config */
		qcom,mode = <1>; /* DIG_OUT */
		qcom,output-type = <0>; /* CMOS */
		qcom,vin-sel = <2>; /* PM8941_S3 1.8V > 1.6V */
		qcom,src-sel = <0>; /* CONSTANT */
		qcom,master-en = <1>; /* ENABLE MPP */
	};

	mpp@a600 { /* MPP 7 */
		/* CAM_FLASH_EN pin */
		qcom,mode = <1>;		/* DIG_OUT */
		qcom,vin-sel = <2>;		/* S3A 1.8v */
		qcom,src-sel = <0>;		/* CONSTANT */
		qcom,master-en = <1>;	/* ENABLE MPP */
	};

	mpp@a700 { /* MPP 8 */
	};
};

&pm8841_mpps {

	mpp@a000 { /* MPP 1 */
	};

	mpp@a100 { /* MPP 2 */
	};

	mpp@a200 { /* MPP 3 */
	};

	mpp@a300 { /* MPP 4 */
	};
};

/* CoreSight */
&tpiu {
	qcom,seta-gpios = <&msmgpio 31 0>,
			  <&msmgpio 32 0>,
			  <&msmgpio 33 0>,
			  <&msmgpio 34 0>,
			  <&msmgpio 35 0>,
			  <&msmgpio 36 0>,
			  <&msmgpio 37 0>,
			  <&msmgpio 38 0>,
			  <&msmgpio 39 0>,
			  <&msmgpio 40 0>,
			  <&msmgpio 41 0>,
			  <&msmgpio 42 0>,
			  <&msmgpio 43 0>,
			  <&msmgpio 44 0>,
			  <&msmgpio 45 0>,
			  <&msmgpio 46 0>,
			  <&msmgpio 47 0>,
			  <&msmgpio 48 0>;
	qcom,seta-gpios-func = <4 4 4 3 4 4 4 3 4 3 5 5 5 5 4 4 5 5>;
	qcom,seta-gpios-drv =  <7 7 7 7 7 7 7 7 7 7 7 7 7 7 7 7 7 7>;
	qcom,seta-gpios-pull = <0 0 0 0 0 0 0 0 0 0 0 0 0 0 0 0 0 0>;
	qcom,seta-gpios-dir =  <2 2 2 2 2 2 2 2 2 2 2 2 2 2 2 2 2 2>;

	qcom,setb-gpios = <&msmgpio 15 0>,
			  <&msmgpio 16 0>,
			  <&msmgpio 17 0>,
			  <&msmgpio 18 0>,
			  <&msmgpio 19 0>,
			  <&msmgpio 20 0>,
			  <&msmgpio 21 0>,
			  <&msmgpio 22 0>,
			  <&msmgpio 23 0>,
			  <&msmgpio 24 0>,
			  <&msmgpio 25 0>,
			  <&msmgpio 26 0>,
			  <&msmgpio 27 0>,
			  <&msmgpio 28 0>,
			  <&msmgpio 89 0>,
			  <&msmgpio 90 0>,
			  <&msmgpio 91 0>,
			  <&msmgpio 92 0>;
	qcom,setb-gpios-func = <2 2 2 2 5 5 5 5 6 6 6 7 7 5 2 3 3 3>;
	qcom,setb-gpios-drv =  <7 7 7 7 7 7 7 7 7 7 7 7 7 7 7 7 7 7>;
	qcom,setb-gpios-pull = <0 0 0 0 0 0 0 0 0 0 0 0 0 0 0 0 0 0>;
	qcom,setb-gpios-dir =  <2 2 2 2 2 2 2 2 2 2 2 2 2 2 2 2 2 2>;
};

&vph_pwr_vreg {
	status = "ok";
};

&slim_msm {
	taiko_codec {
		qcom,cdc-reset-gpio = <&msmgpio 78 0>;
		qcom,cdc-micbias1-ext-cap;
		qcom,cdc-micbias2-ext-cap;
		qcom,cdc-micbias3-ext-cap;
		qcom,cdc-micbias4-ext-cap;

		/*
		 * Liquid has external spkrdrv supply. Give a dummy supply to
		 * make codec driver's happy.
		 */
		cdc-vdd-spkdrv-supply = <&vph_pwr_vreg>;
		qcom,cdc-vdd-spkdrv-voltage = <0 0>;
		qcom,cdc-vdd-spkdrv-current = <0>;

		qcom,cdc-on-demand-supplies = "cdc-vdd-spkdrv";
	};
};

&pm8941_lsid0 {
	qcom,power-on@800 {
		qcom,pon_1 {
			qcom,pon-type = <0>;
			qcom,disable-reset = <1>;
			qcom,pull-up = <1>;
			linux,code = <116>;
		};

		qcom,pon_2 {
			qcom,pon-type = <1>;
			qcom,disable-reset = <1>;
			qcom,pull-up = <1>;
			linux,code = <114>;
		};

		qcom,pon_3 {
			qcom,pon-type = <3>;
			qcom,support-reset = <1>;
			qcom,s1-timer = <6720>;
			qcom,s2-timer = <1000>;
			qcom,s2-type = <1>;
			qcom,pull-up = <1>;
		};
	};
};
